VERSION ""

NS_ :

BS_:

BU_: Receiver ChassisBus VehicleBus PartyBus

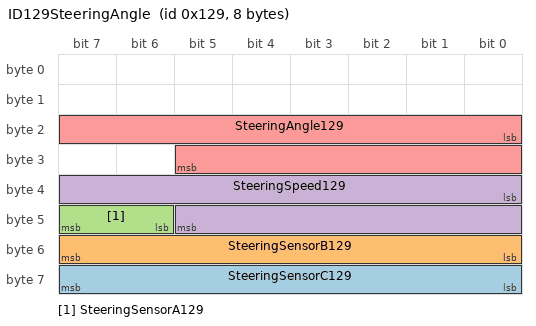
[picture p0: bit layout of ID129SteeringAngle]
BO_ 297 ID129SteeringAngle: 8 VehicleBus
 SG_ SteeringSensorC129 : 56|8@1+ (1,0) [0|255] ""  Receiver
 SG_ SteeringSensorB129 : 48|8@1+ (1,0) [0|255] ""  Receiver
 SG_ SteeringSensorA129 : 46|2@1+ (1,0) [0|3] ""  Receiver
 SG_ SteeringSpeed129 : 32|14@1+ (0.5,-4096) [-4096|4095.5] "D/S"  Receiver
 SG_ SteeringAngle129 : 16|14@1+ (0.1,-819.2) [-819.2|819.1] "Deg"  Receiver

CM_ SG_ 297 SteeringSpeed129 "Steering Speed";
CM_ SG_ 297 SteeringAngle129 "Steering Angle";

BA_DEF_  "BusType" STRING ;
BA_DEF_ BO_  "GenMsgSendType" ENUM  "Cyclic","SendType1","SendType2","SendType3","SendType4","SendType5","SendType6","SendType7","SendType8","SendType9";
BA_DEF_ BO_  "GenMsgCycleTime" INT 0 0;
BA_DEF_DEF_  "GenMsgSendType" "";
BA_DEF_DEF_  "GenMsgCycleTime" 0;
BA_ "BusType" "CAN";
BA_ "GenMsgSendType" BO_ 297 0;
BA_ "GenMsgCycleTime" BO_ 297 10;
